VERSION ""

NS_ :

BS_:

BU_: BPS_LVBatteryMonitor Controls_MotorCommander Telemetry_Leader TPEE_MPPT_B Prohelion_WaveSculptor22 TPEE_MPPT_A Power_Precharge Controls_DriverUserInterface BPS_Leader
VAL_TABLE_ Fault 1 "TRIPPED" 0 "OK" ;
VAL_TABLE_ Generic_Active 1 "Active" 0 "Inactive" ;
VAL_TABLE_ BPS_Fault 11 "MPPT" 10 "E-STOP/Contactor" 9 "IsoSPI" 8 "Watchdog" 7 "OS" 6 "Handler" 5 "Open Wire" 4 "Over Current" 3 "Over Temperature" 2 "Overvoltage" 1 "Undervoltage" 0 "None" ;
VAL_TABLE_ Contactor_State 1 "Closed" 0 "Open" ;
VAL_TABLE_ Generic_EN 1 "Enabled" 0 "Disabled" ;
VAL_TABLE_ MPPT_Fault 6 "Fault" 5 "Temperature De-rating" 4 "Constant Output Current" 3 "Constand Output Voltage" 2 "Minimum Input Current" 1 "Constand Input Current" 0 "Constand Input Voltage" ;
VAL_TABLE_ MPPT_Mode 8 "Fault" 7 "Phase Over Current" 6 "Input Under Current" 5 "Input Over Current" 4 "Output Over Current" 3 "Output Over Voltage" 2 "Input Over Voltage" 1 "Configuration Error" 0 "OK(No Fault)" ;

BO_ 1793 DAQ_RF_Bytes_Transmited: 4 Telemetry_Leader
 SG_ DAQ_Bytes_Transmited : 0|32@1+ (1,0) [0|10000] "Bytes" Vector__XXX

BO_ 1794 DAQ_RF_Transmission_Fail_Count: 2 Telemetry_Leader
 SG_ DAQ_TX_Fail_Count : 0|16@1+ (1,0) [0|10000] "" Vector__XXX

BO_ 1795 DAQ_RF_Last_Packet_RSSI: 1 Telemetry_Leader
 SG_ DAQ_RSSI : 0|8@1+ (1,0) [0|255] "-dBm" Vector__XXX

BO_ 1796 DAQ_RF_Good_Packet_RX_Count: 2 Telemetry_Leader
 SG_ DAQ_Good_Packet_Receive_Count : 0|16@1+ (1,0) [0|10000] "" Vector__XXX

BO_ 1797 DAQ_RF_MAC_ACK_Failure_Count: 2 Telemetry_Leader
 SG_ DAQ_MAC_ACK_Fail_Count : 0|16@1+ (1,0) [0|10000] "" Vector__XXX

BO_ 1921 DAQ_LTECellularSignalStrength: 1 Telemetry_Leader
 SG_ DAQ_LTE_RSSI : 0|8@1+ (1,0) [0|255] "-dBm" Vector__XXX

BO_ 1930 DAQ_ServerHeartbeat: 1 Telemetry_Leader
 SG_ DAQ_Heartbeat : 0|1@0+ (1,0) [0|1] "" Vector__XXX

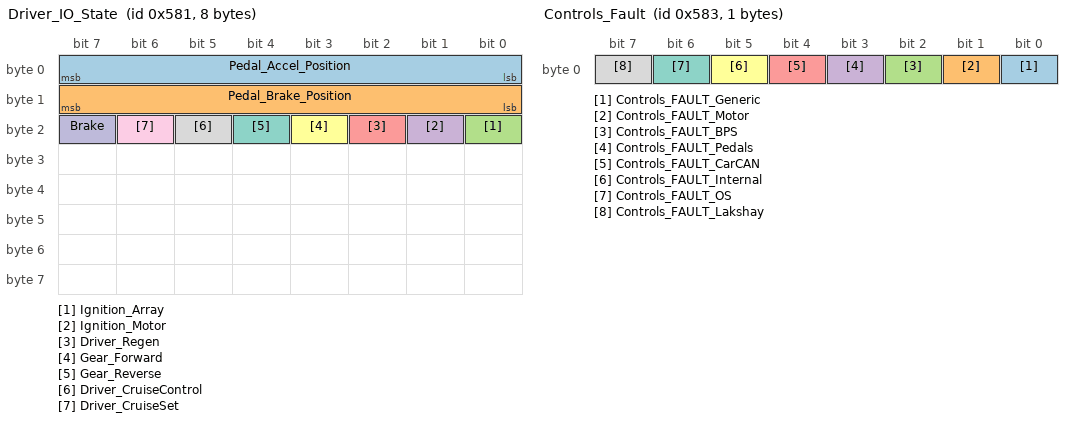
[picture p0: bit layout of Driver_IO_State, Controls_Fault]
BO_ 1409 Driver_IO_State: 8 Controls_DriverUserInterface
 SG_ Pedal_Accel_Position : 0|8@1+ (1,0) [0|100] "%" Vector__XXX
 SG_ Pedal_Brake_Position : 8|8@1+ (1,0) [0|100] "%" Vector__XXX
 SG_ Ignition_Array : 16|1@1+ (1,0) [0|1] "" Vector__XXX
 SG_ Ignition_Motor : 17|1@1+ (1,0) [0|1] "" Vector__XXX
 SG_ Driver_Regen : 18|1@1+ (1,0) [0|1] "" Vector__XXX
 SG_ Gear_Forward : 19|1@1+ (1,0) [0|1] "" Vector__XXX
 SG_ Gear_Reverse : 20|1@1+ (1,0) [0|1] "" Vector__XXX
 SG_ Driver_CruiseControl : 21|1@1+ (1,0) [0|1] "" Vector__XXX
 SG_ Driver_CruiseSet : 22|1@1+ (1,0) [0|1] "" Vector__XXX
 SG_ Brake : 23|1@1+ (1,0) [0|1] "" Vector__XXX

BO_ 1411 Controls_Fault: 1 Controls_DriverUserInterface
 SG_ Controls_FAULT_Generic : 0|1@1+ (1,0) [0|1] "" Vector__XXX
 SG_ Controls_FAULT_Motor : 1|1@1+ (1,0) [0|1] "" Vector__XXX
 SG_ Controls_FAULT_BPS : 2|1@1+ (1,0) [0|1] "" Vector__XXX
 SG_ Controls_FAULT_Pedals : 3|1@1+ (1,0) [0|1] "" Vector__XXX
 SG_ Controls_FAULT_CarCAN : 4|1@1+ (1,0) [0|1] "" Vector__XXX
 SG_ Controls_FAULT_Internal : 5|1@1+ (1,0) [0|1] "" Vector__XXX
 SG_ Controls_FAULT_OS : 6|1@1+ (1,0) [0|1] "" Vector__XXX
 SG_ Controls_FAULT_Lakshay : 7|1@1+ (1,0) [0|1] "" Vector__XXX

BO_ 1412 Controls_Motor_Safe: 1 Controls_DriverUserInterface
 SG_ Controls_Motor_Safe : 0|1@1+ (1,0) [0|1] "" Vector__XXX
 SG_ Controls_Motor_Unsafe_Error : 1|1@1+ (1,0) [0|1] "" Vector__XXX

BO_ 546 MC_PowerCommand: 4 Controls_MotorCommander
 SG_ MC_MotorPowerSetpoint : 0|32@1- (1,0) [0|1] "%"  Prohelion_WaveSculptor22

BO_ 576 MC_Info: 8 Prohelion_WaveSculptor22
 SG_ MC_TritiumID : 0|32@1+ (1,0) [0|0] "" Vector__XXX
 SG_ MC_SerialNumber : 32|32@1+ (1,0) [0|0] "" Vector__XXX

BO_ 577 MC_Status: 8 Prohelion_WaveSculptor22
 SG_ MC_LIMIT_Reserved : 7|9@1+ (1,0) [0|511] "" Vector__XXX
 SG_ MC_LIMIT_MotorTemp : 6|1@1+ (1,0) [0|1] "" Vector__XXX
 SG_ MC_LIMIT_BusVoltageLower : 5|1@1+ (1,0) [0|1] "" Vector__XXX
 SG_ MC_LIMIT_BusVoltageUpper : 4|1@1+ (1,0) [0|1] "" Vector__XXX
 SG_ MC_LIMIT_BusCurrent : 3|1@1+ (1,0) [0|1] "" Vector__XXX
 SG_ MC_LIMIT_Velocity : 2|1@1+ (1,0) [0|1] "" Vector__XXX
 SG_ MC_LIMIT_MotorCurrent : 1|1@1+ (1,0) [0|1] "" Vector__XXX
 SG_ MC_LIMIT_OutputVoltagePWM : 0|1@1+ (1,0) [0|1] "" Vector__XXX
 SG_ MC_FAULT_Reserved : 25|7@1+ (1,0) [0|0] "" Vector__XXX
 SG_ MC_FAULT_MotorOverSpeed : 24|1@1+ (1,0) [0|1] "" Vector__XXX
 SG_ MC_FAULT_DesaturationFault : 23|1@1+ (1,0) [0|1] "" Vector__XXX
 SG_ MC_FAULT_15vRailUnderVoltage : 22|1@1+ (1,0) [0|1] "" Vector__XXX
 SG_ MC_FAULT_ConfigRead : 21|1@1+ (1,0) [0|1] "" Vector__XXX
 SG_ MC_FAULT_WatchdogCausedLastReset : 20|1@1+ (1,0) [0|1] "" Vector__XXX
 SG_ MC_FAULT_BadMotorPositionHallSeq : 19|1@1+ (1,0) [0|1] "" Vector__XXX
 SG_ MC_FAULT_DcBusOverVoltage : 18|1@1+ (1,0) [0|1] "" Vector__XXX
 SG_ MC_FAULT_SoftwareOverCurrent : 17|1@1+ (1,0) [0|1] "" Vector__XXX
 SG_ MC_FAULT_HardwareOverCurrent : 16|1@1+ (1,0) [0|1] "" Vector__XXX
 SG_ MC_ActiveMotor : 32|16@1+ (1,0) [0|0] "" Vector__XXX
 SG_ MC_TxErrorCount : 48|8@1+ (1,0) [0|0] "" Vector__XXX
 SG_ MC_RxErrorCount : 56|8@1+ (1,0) [0|0] "" Vector__XXX

BO_ 578 MC_BusMeasurement: 8 Prohelion_WaveSculptor22
 SG_ MC_BusVoltage : 0|32@1- (1,0) [0|0] "V" Vector__XXX
 SG_ MC_BusCurrent : 32|32@1- (1,0) [0|0] "A" Vector__XXX

BO_ 579 MC_VelocityMeasurement: 8 Prohelion_WaveSculptor22
 SG_ MC_MotorVelocity : 0|32@1- (1,0) [0|0] "rpm" Vector__XXX
 SG_ MC_VehicleVelocity : 32|32@1- (1,0) [0|0] "m/s" Vector__XXX

BO_ 1413 Controls_Pedals_Raw: 4 Controls_DriverUserInterface
 SG_ Pedal_Brake_Raw : 0|15@1+ (1,0) [0|3300] "mV" Vector__XXX
 SG_ Pedal_Accel_Raw : 16|15@1+ (1,0) [0|3300] "mV" Vector__XXX

BO_ 1025 Precharge_Timeout: 1 Power_Precharge
 SG_ Motor_Precharge_Timeout : 0|1@1+ (1,0) [0|1] "" Vector__XXX
 SG_ Array_Precharge_Timeout : 1|1@1+ (1,0) [0|0] "" Vector__XXX

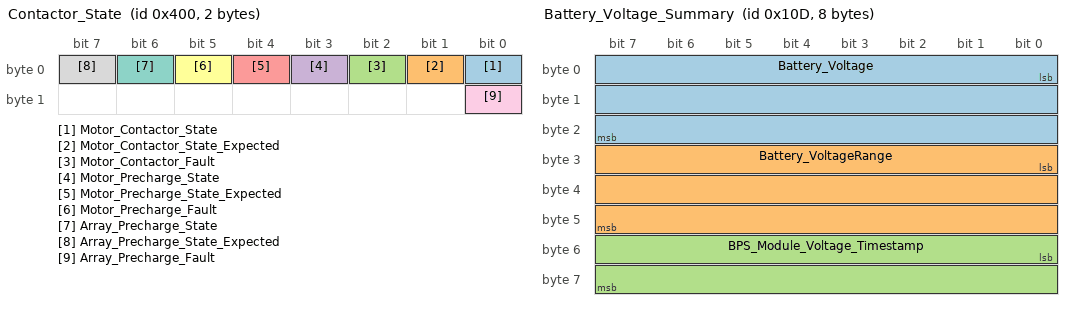
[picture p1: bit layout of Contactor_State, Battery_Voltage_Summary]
BO_ 1024 Contactor_State: 2 Power_Precharge
 SG_ Motor_Contactor_State : 0|1@1+ (1,0) [0|1] "" Vector__XXX
 SG_ Motor_Contactor_State_Expected : 1|1@1+ (1,0) [0|0] "" Vector__XXX
 SG_ Motor_Contactor_Fault : 2|1@1+ (1,0) [0|1] "" Vector__XXX
 SG_ Motor_Precharge_State : 3|1@1+ (1,0) [0|1] "" Vector__XXX
 SG_ Motor_Precharge_State_Expected : 4|1@1+ (1,0) [0|1] "" Vector__XXX
 SG_ Motor_Precharge_Fault : 5|1@1+ (1,0) [0|1] "" Vector__XXX
 SG_ Array_Precharge_State : 6|1@1+ (1,0) [0|1] "" Vector__XXX
 SG_ Array_Precharge_State_Expected : 7|1@1+ (1,0) [0|1] "" Vector__XXX
 SG_ Array_Precharge_Fault : 8|1@1+ (1,0) [0|1] "" Vector__XXX

BO_ 2 BPS_Trip: 1 BPS_Leader
 SG_ BPS_Trip : 0|1@0+ (1,0) [0|1] "" Vector__XXX

BO_ 257 BPS_All_Clear: 1 BPS_Leader
 SG_ BPS_AllClear : 0|1@0+ (1,0) [0|1] "" Vector__XXX

BO_ 258 BPS_Contactor_State: 1 BPS_Leader
 SG_ BPS_ArrayContactor : 0|1@0+ (1,0) [0|1] "" Vector__XXX
 SG_ BPS_HVContactors : 2|1@0+ (1,0) [0|1] "" Vector__XXX

BO_ 259 Battery_Current: 4 BPS_Leader
 SG_ Battery_Current : 0|32@1- (0.001,0) [-50000|100000] "A" Vector__XXX

BO_ 260 Battery_Voltage_Array: 6 BPS_Leader
 SG_ BPS_Volt_Array_idx : 0|8@1+ (1,0) [0|31] "" Vector__XXX
 SG_ Battery_ModuleVoltage : 8|32@1+ (0.001,0) [0|1000000] "V" Vector__XXX

BO_ 261 Battery_Temperature_Array: 6 BPS_Leader
 SG_ BPS_Temp_Array_idx : 0|8@1+ (1,0) [0|31] "" Vector__XXX
 SG_ Battery_ModuleTemperature : 8|32@1+ (0.001,0) [0|1000000] "C" Vector__XXX

BO_ 262 Battery_SoC: 4 BPS_Leader
 SG_ BPS_SoC : 0|32@1+ (1E-06,0) [0|100] "%" Vector__XXX

BO_ 263 BPS_WDog_Trip: 1 BPS_Leader
 SG_ BPS_WDog_Trig : 0|1@0+ (1,0) [0|1] "" Vector__XXX

BO_ 264 BPS_CAN_Error: 1 BPS_Leader
 SG_ BPS_CANError : 0|1@0+ (1,0) [0|1] "" Vector__XXX

BO_ 267 Supplemental_Voltage: 2 BPS_LVBatteryMonitor
 SG_ Supplemental_Voltage : 0|16@1+ (0.001,0) [0|65535] "V" Vector__XXX

BO_ 268 BPS_Charge_Enabled: 1 BPS_Leader
 SG_ Battery_ChargeEnabled : 0|1@0+ (1,0) [0|1] "" Vector__XXX

BO_ 269 Battery_Voltage_Summary: 8 BPS_Leader
 SG_ Battery_Voltage : 0|24@1+ (0.001,0) [0|16777215] "V" Vector__XXX
 SG_ Battery_VoltageRange : 24|24@1+ (1,0) [0|16777215] "mV" Vector__XXX
 SG_ BPS_Module_Voltage_Timestamp : 48|16@1+ (1,0) [0|65535] "ms" Vector__XXX

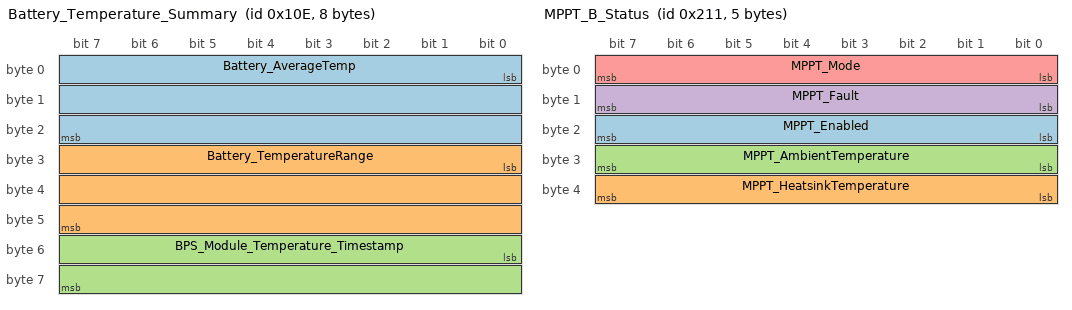
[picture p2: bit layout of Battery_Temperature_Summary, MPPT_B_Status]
BO_ 270 Battery_Temperature_Summary: 8 BPS_Leader
 SG_ Battery_AverageTemp : 0|24@1+ (0.001,0) [0|69696969] "C" Vector__XXX
 SG_ Battery_TemperatureRange : 24|24@1+ (0.001,0) [0|0] "C" Vector__XXX
 SG_ BPS_Module_Temperature_Timestamp : 48|16@1+ (1,0) [0|0] "ms" Vector__XXX

BO_ 271 BPS_Fault_State: 1 BPS_Leader
 SG_ BPS_Fault : 0|8@1+ (1,0) [0|12] "" Vector__XXX

BO_ 547 MC_ResetCommand: 1 Controls_MotorCommander
 SG_ MC_Reset : 0|8@1+ (1,0) [0|0] "" Vector__XXX

BO_ 545 MC_DriveCommand: 8 Controls_MotorCommander
 SG_ MC_MotorCurrentSetpoint : 32|32@1- (1,0) [0|1] "%"  Prohelion_WaveSculptor22
 SG_ MC_MotorVelocitySetpoint : 0|32@1- (1,0) [0|12000] "rpm"  Prohelion_WaveSculptor22

BO_ 580 MC_PhaseCurrentMeasurement: 8 Prohelion_WaveSculptor22
 SG_ MC_PhaseCurrentB : 0|32@1- (1,0) [0|0] "A_rms" Vector__XXX
 SG_ MC_PhaseCurrentC : 32|32@1- (1,0) [0|0] "A_rms" Vector__XXX

BO_ 581 MC_MotorVoltageVectorMeasurement: 8 Prohelion_WaveSculptor22
 SG_ MC_Vq : 0|32@1- (1,0) [0|0] "V" Vector__XXX
 SG_ MC_Vd : 32|32@1- (1,0) [0|0] "V" Vector__XXX

BO_ 582 MC_MotorCurrentVectorMeasurement: 8 Prohelion_WaveSculptor22
 SG_ MC_Iq : 0|32@1- (1,0) [0|0] "A" Vector__XXX
 SG_ MC_Id : 32|32@1- (1,0) [0|0] "A" Vector__XXX

BO_ 583 MC_BackEMFMeasurementPrediction: 8 Prohelion_WaveSculptor22
 SG_ MC_BEMFq : 0|32@1- (1,0) [0|0] "V" Vector__XXX
 SG_ MC_BEMFd : 32|32@1- (1,0) [0|0] "V" Vector__XXX

BO_ 584 MC_15VRailMeasurement: 8 Prohelion_WaveSculptor22
 SG_ MC_Supply15V : 32|32@1- (1,0) [0|0] "V" Vector__XXX

BO_ 585 MC_3V319VRailMeasurement: 8 Prohelion_WaveSculptor22
 SG_ MC_Supply1V9 : 0|32@1- (1,0) [0|0] "V" Vector__XXX
 SG_ MC_Supply3V3 : 32|32@1- (1,0) [0|0] "V" Vector__XXX

BO_ 587 MC_Motor_TempMeasurement: 8 Prohelion_WaveSculptor22
 SG_ MC_MotorTemp : 0|32@1- (1,0) [0|0] "C" Vector__XXX
 SG_ MC_HeatsinkTemp : 32|32@1- (1,0) [0|0] "C" Vector__XXX

BO_ 588 MC_DspBoardTempMeasurement: 8 Prohelion_WaveSculptor22
 SG_ MC_DspBoardTemp : 0|32@1- (1,0) [0|0] "C" Vector__XXX

BO_ 590 MC_OdometerBusAhMeasurement: 8 Prohelion_WaveSculptor22
 SG_ MC_TripOdometer : 0|32@1- (1,0) [0|0] "m" Vector__XXX
 SG_ MC_DCBusAh : 32|32@1- (1,0) [0|0] "Ah" Vector__XXX

BO_ 599 MC_SlipSpeedMeasurement: 8 Prohelion_WaveSculptor22
 SG_ MC_SlipSpeed : 0|32@1- (1,0) [0|0] "Hz" Vector__XXX

BO_ 537 MPPT_B_SetMode: 1 BPS_Leader
 SG_ MPPT_SetMode : 0|8@1+ (1,0) [0|1] ""  TPEE_MPPT_B

BO_ 521 MPPT_A_SetMode: 1 BPS_Leader
 SG_ MPPT_SetMode : 0|8@1+ (1,0) [0|1] ""  TPEE_MPPT_A

BO_ 529 MPPT_B_Status: 5 TPEE_MPPT_B
 SG_ MPPT_Enabled : 16|8@1- (1,0) [0|0] "" Vector__XXX
 SG_ MPPT_HeatsinkTemperature : 39|8@0- (1,0) [-128|127] "C" Vector__XXX
 SG_ MPPT_AmbientTemperature : 31|8@0- (1,0) [-128|127] "C" Vector__XXX
 SG_ MPPT_Fault : 8|8@1+ (1,0) [0|0] "" Vector__XXX
 SG_ MPPT_Mode : 0|8@1+ (1,0) [0|0] "" Vector__XXX

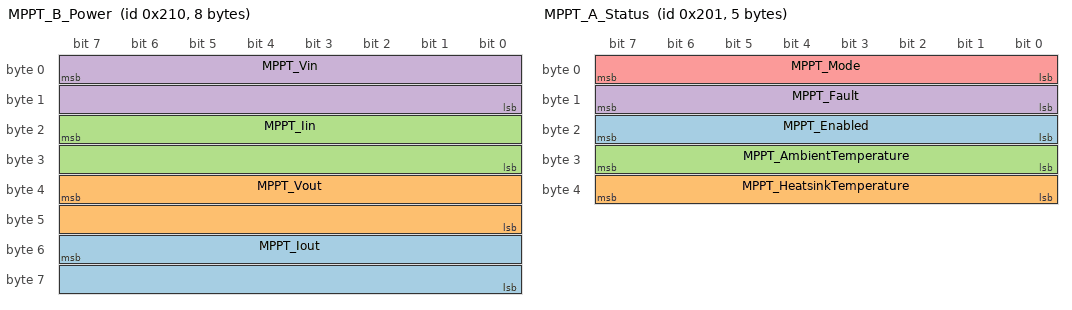
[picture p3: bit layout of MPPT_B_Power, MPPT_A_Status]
BO_ 528 MPPT_B_Power: 8 TPEE_MPPT_B
 SG_ MPPT_Iout : 55|16@0- (0.0005,0) [0|0] "A" Vector__XXX
 SG_ MPPT_Vout : 39|16@0- (0.01,0) [-327.68|327.67] "V" Vector__XXX
 SG_ MPPT_Iin : 23|16@0- (0.0005,0) [-16.384|16.3835] "A" Vector__XXX
 SG_ MPPT_Vin : 7|16@0- (0.01,0) [-327.68|327.67] "V" Vector__XXX

BO_ 513 MPPT_A_Status: 5 TPEE_MPPT_A
 SG_ MPPT_Enabled : 16|8@1- (1,0) [0|0] "" Vector__XXX
 SG_ MPPT_HeatsinkTemperature : 39|8@0- (1,0) [-128|127] "C" Vector__XXX
 SG_ MPPT_AmbientTemperature : 31|8@0- (1,0) [-128|127] "C" Vector__XXX
 SG_ MPPT_Fault : 8|8@1+ (1,0) [0|0] "" Vector__XXX
 SG_ MPPT_Mode : 0|8@1+ (1,0) [0|0] "" Vector__XXX

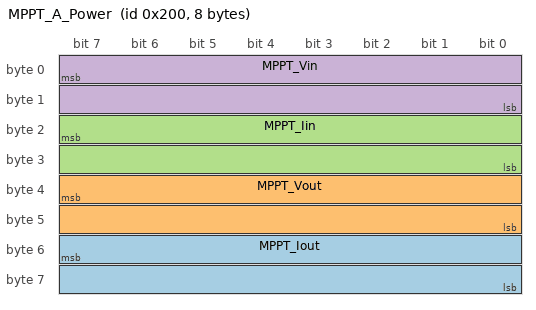
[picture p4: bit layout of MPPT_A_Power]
BO_ 512 MPPT_A_Power: 8 TPEE_MPPT_A
 SG_ MPPT_Iout : 55|16@0- (0.0005,0) [0|0] "A" Vector__XXX
 SG_ MPPT_Vout : 39|16@0- (0.01,0) [-327.68|327.67] "V" Vector__XXX
 SG_ MPPT_Iin : 23|16@0- (0.0005,0) [-16.384|16.3835] "A" Vector__XXX
 SG_ MPPT_Vin : 7|16@0- (0.01,0) [-327.68|327.67] "V" Vector__XXX

CM_ BO_ 1793 "RF1";
CM_ BO_ 1794 "RF2";
CM_ BO_ 1795 "RF3";
CM_ BO_ 1796 "RF4";
CM_ BO_ 1797 "RF5";
CM_ BO_ 1921 "LTE1";
CM_ BO_ 1930 "SHB";
CM_ SG_ 576 MC_TritiumID "Device identifier. 0x00004003";
CM_ SG_ 576 MC_SerialNumber "Device serial number, allocated at manufacture.";
CM_ SG_ 577 MC_ActiveMotor "The index of the active motor currently being used.";
CM_ SG_ 577 MC_TxErrorCount "The DSP CAN transmission error counter (CAN 2.0)";
CM_ SG_ 577 MC_RxErrorCount "The DSP CAN receive error counter (CAN 2.0)";
CM_ SG_ 578 MC_BusVoltage "DC bus voltage at the controller.";
CM_ SG_ 578 MC_BusCurrent "Current drawn from the DC bus by the controller.";
CM_ SG_ 579 MC_MotorVelocity "Motor angular frequency in revolutions per minute.";
CM_ SG_ 579 MC_VehicleVelocity "Vehicle velocity in metres / second.";
CM_ SG_ 580 MC_PhaseCurrentB "RMS current in motor Phase B.";
CM_ SG_ 580 MC_PhaseCurrentC "RMS current in motor Phase C.";
CM_ SG_ 581 MC_Vq "Imaginary component of the applied non-rotating voltage vector to the motor.";
CM_ SG_ 581 MC_Vd "Real component of the applied non-rotating voltage vector to the motor.";
CM_ SG_ 582 MC_Iq "Imaginary component of the applied non-rotating current vector to the motor. This current produces torque in the motor and should be in phase with the back-EMF of the motor";
CM_ SG_ 582 MC_Id "Real component of the applied non-rotating current vector to the motor. This vector represents the field current of the motor.";
CM_ SG_ 583 MC_BEMFq "The peak of the phase to neutral motor voltage.";
CM_ SG_ 583 MC_BEMFd "By definition this value is always 0V.";
CM_ SG_ 584 MC_Supply15V "Actual voltage level of the 15V power rail.";
CM_ SG_ 585 MC_Supply1V9 "Actual voltage level of the 1.9V DSP power rail.";
CM_ SG_ 585 MC_Supply3V3 "Actual voltage level of the 3.3V power rail.";
CM_ SG_ 587 MC_MotorTemp "Internal temperature of the motor";
CM_ SG_ 587 MC_HeatsinkTemp "Internal temperature of Heat-sink (case).";
CM_ SG_ 588 MC_DspBoardTemp "Temperature of the DSP board.";
CM_ SG_ 590 MC_TripOdometer "Distance the vehicle has travelled since reset.";
CM_ SG_ 590 MC_DCBusAh "Charge flow into the controller DC bus from the time of reset.";
CM_ SG_ 599 MC_SlipSpeed "Slip speed when driving an induction motor.";
BA_DEF_  "DBName" STRING ;
BA_DEF_ BO_  "GenMsgSendType" ENUM  "Cyclic","Event","CyclicAndEvent","CyclicAndEventNoRepetition","None","Spontaneous";
BA_DEF_ BU_  "Timeout" INT 100 100000;
BA_DEF_  "ProtocolType" ENUM  "ISO 11898-2","J1939";
BA_DEF_DEF_  "DBName" "";
BA_DEF_DEF_  "GenMsgSendType" "Cyclic";
BA_DEF_DEF_  "Timeout" 1000;
BA_DEF_DEF_  "ProtocolType" "ISO 11898-2";
BA_ "DBName" "CarCAN";
BA_ "Timeout" BU_ Controls_MotorCommander 250;
BA_ "Timeout" BU_ TPEE_MPPT_B 500;
BA_ "Timeout" BU_ Prohelion_WaveSculptor22 200;
BA_ "Timeout" BU_ TPEE_MPPT_A 500;
BA_ "Timeout" BU_ Power_Precharge 250;
BA_ "Timeout" BU_ Controls_DriverUserInterface 250;
BA_ "Timeout" BU_ BPS_Leader 250;
VAL_ 1409 Ignition_Array 1 "Enabled" 0 "Disabled" ;
VAL_ 1409 Ignition_Motor 1 "Enabled" 0 "Disabled" ;
VAL_ 1409 Driver_Regen 1 "Enabled" 0 "Disabled" ;
VAL_ 1409 Gear_Forward 1 "Active" 0 "Inactive" ;
VAL_ 1409 Gear_Reverse 1 "Active" 0 "Inactive" ;
VAL_ 1409 Driver_CruiseControl 1 "Enabled" 0 "Disabled" ;
VAL_ 1409 Driver_CruiseSet 1 "Enabled" 0 "Disabled" ;
VAL_ 1409 Brake 1 "Active" 0 "Inactive" ;
VAL_ 577 MC_FAULT_Reserved 1 "TRIPPED" 0 "OK" ;
VAL_ 577 MC_FAULT_MotorOverSpeed 1 "TRIPPED" 0 "OK" ;
VAL_ 577 MC_FAULT_DesaturationFault 1 "TRIPPED" 0 "OK" ;
VAL_ 577 MC_FAULT_15vRailUnderVoltage 1 "TRIPPED" 0 "OK" ;
VAL_ 577 MC_FAULT_ConfigRead 1 "TRIPPED" 0 "OK" ;
VAL_ 577 MC_FAULT_WatchdogCausedLastReset 1 "TRIPPED" 0 "OK" ;
VAL_ 577 MC_FAULT_BadMotorPositionHallSeq 1 "TRIPPED" 0 "OK" ;
VAL_ 577 MC_FAULT_DcBusOverVoltage 1 "TRIPPED" 0 "OK" ;
VAL_ 577 MC_FAULT_SoftwareOverCurrent 1 "TRIPPED" 0 "OK" ;
VAL_ 577 MC_FAULT_HardwareOverCurrent 1 "TRIPPED" 0 "OK" ;
VAL_ 1024 Motor_Contactor_State 1 "Closed" 0 "Open" ;
VAL_ 1024 Motor_Contactor_State_Expected 1 "Closed" 0 "Open" ;
VAL_ 1024 Motor_Precharge_State 1 "Closed" 0 "Open" ;
VAL_ 1024 Motor_Precharge_State_Expected 1 "Closed" 0 "Open" ;
VAL_ 1024 Array_Precharge_State 1 "Closed" 0 "Open" ;
VAL_ 1024 Array_Precharge_State_Expected 1 "Closed" 0 "Open" ;
VAL_ 258 BPS_ArrayContactor 1 "Closed" 0 "Open" ;
VAL_ 258 BPS_HVContactors 1 "Closed" 0 "Open" ;
VAL_ 268 Battery_ChargeEnabled 1 "Enabled" 0 "Disabled" ;
VAL_ 2 BPS_Trip 0 "No Fault" 1 "Fault";
VAL_ 271 BPS_Fault 11 "MPPT" 10 "E-STOP/Contactor" 9 "IsoSPI" 8 "Watchdog" 7 "OS" 6 "Handler" 5 "Open Wire" 4 "Over Current" 3 "Over Temperature" 2 "Overvoltage" 1 "Undervoltage" 0 "None" ;
VAL_ 537 MPPT_SetMode 1 "Enabled" 0 "Disabled" ;
VAL_ 521 MPPT_SetMode 1 "Enabled" 0 "Disabled" ;
VAL_ 529 MPPT_Enabled 1 "Enabled" 0 "Disabled" ;
VAL_ 529 MPPT_Fault 6 "Fault" 5 "Temperature De-rating" 4 "Constant Output Current" 3 "Constand Output Voltage" 2 "Minimum Input Current" 1 "Constand Input Current" 0 "Constand Input Voltage" ;
VAL_ 529 MPPT_Mode 8 "Fault" 7 "Phase Over Current" 6 "Input Under Current" 5 "Input Over Current" 4 "Output Over Current" 3 "Output Over Voltage" 2 "Input Over Voltage" 1 "Configuration Error" 0 "OK(No Fault)" ;
VAL_ 513 MPPT_Enabled 1 "Enabled" 0 "Disabled" ;
VAL_ 513 MPPT_Fault 6 "Fault" 5 "Temperature De-rating" 4 "Constant Output Current" 3 "Constand Output Voltage" 2 "Minimum Input Current" 1 "Constand Input Current" 0 "Constand Input Voltage" ;
VAL_ 513 MPPT_Mode 8 "Fault" 7 "Phase Over Current" 6 "Input Under Current" 5 "Input Over Current" 4 "Output Over Current" 3 "Output Over Voltage" 2 "Input Over Voltage" 1 "Configuration Error" 0 "OK(No Fault)" ;
SIG_VALTYPE_ 546 MC_MotorPowerSetpoint : 1;
SIG_VALTYPE_ 578 MC_BusVoltage : 1;
SIG_VALTYPE_ 578 MC_BusCurrent : 1;
SIG_VALTYPE_ 579 MC_MotorVelocity : 1;
SIG_VALTYPE_ 579 MC_VehicleVelocity : 1;
SIG_VALTYPE_ 545 MC_MotorCurrentSetpoint : 1;
SIG_VALTYPE_ 545 MC_MotorVelocitySetpoint : 1;
SIG_VALTYPE_ 580 MC_PhaseCurrentB : 1;
SIG_VALTYPE_ 580 MC_PhaseCurrentC : 1;
SIG_VALTYPE_ 581 MC_Vq : 1;
SIG_VALTYPE_ 581 MC_Vd : 1;
SIG_VALTYPE_ 582 MC_Iq : 1;
SIG_VALTYPE_ 582 MC_Id : 1;
SIG_VALTYPE_ 583 MC_BEMFq : 1;
SIG_VALTYPE_ 583 MC_BEMFd : 1;
SIG_VALTYPE_ 584 MC_Supply15V : 1;
SIG_VALTYPE_ 585 MC_Supply1V9 : 1;
SIG_VALTYPE_ 585 MC_Supply3V3 : 1;
SIG_VALTYPE_ 587 MC_MotorTemp : 1;
SIG_VALTYPE_ 587 MC_HeatsinkTemp : 1;
SIG_VALTYPE_ 588 MC_DspBoardTemp : 1;
SIG_VALTYPE_ 590 MC_TripOdometer : 1;
SIG_VALTYPE_ 590 MC_DCBusAh : 1;
SIG_VALTYPE_ 599 MC_SlipSpeed : 1;
